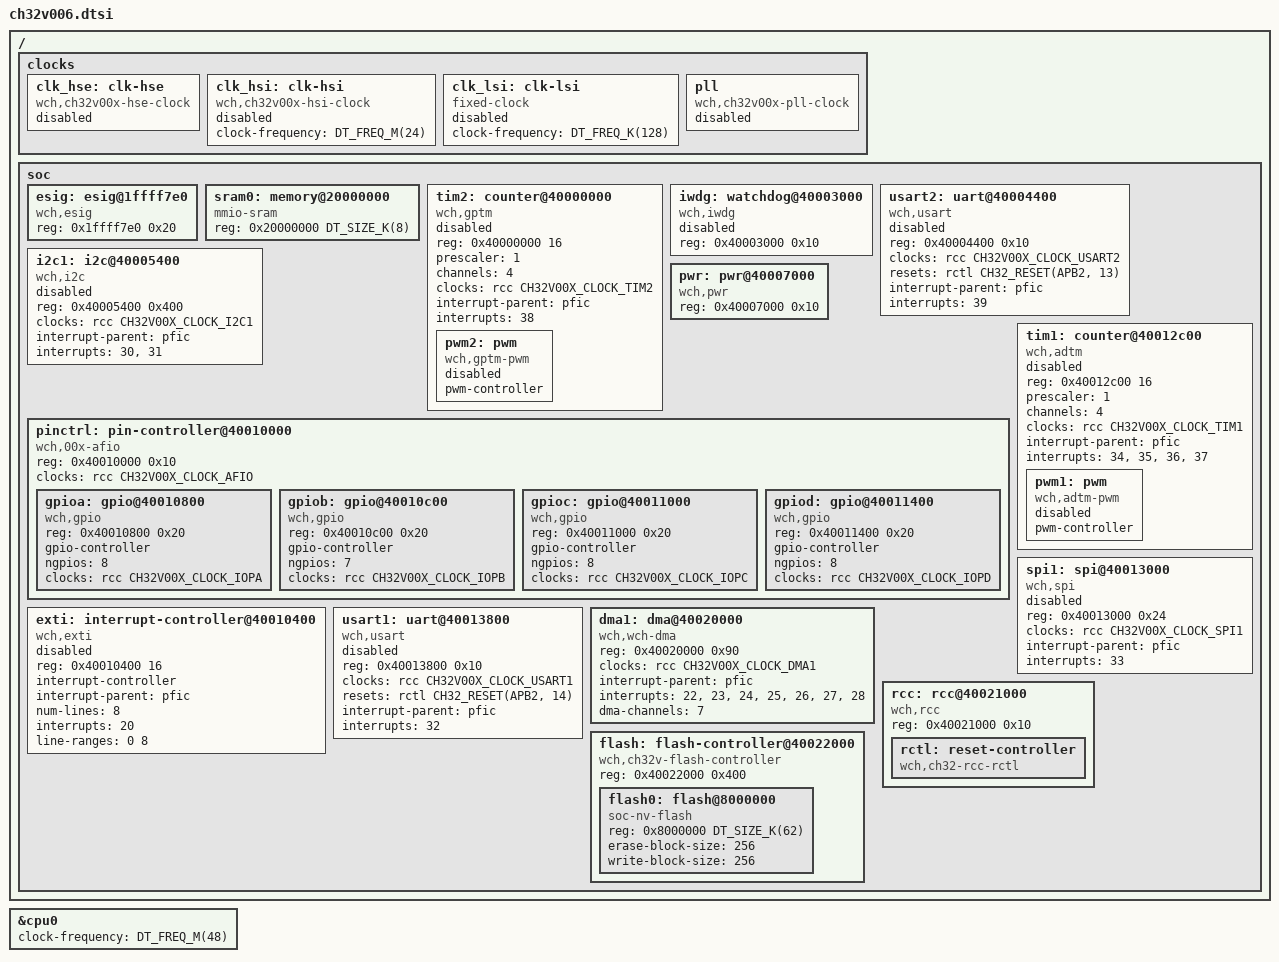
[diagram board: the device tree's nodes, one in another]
/*
 * Copyright (c) 2025 Michael Hope <michaelh@juju.nz>
 * Copyright (c) 2024 Paul Wedeck <paulwedeck@gmail.com>
 *
 * SPDX-License-Identifier: Apache-2.0
 */

#include <freq.h>
#include <mem.h>
#include <wch/qingke-v2c.dtsi>
#include <zephyr/dt-bindings/gpio/gpio.h>
#include <zephyr/dt-bindings/i2c/i2c.h>
#include <zephyr/dt-bindings/clock/ch32v00x-clocks.h>
#include <zephyr/dt-bindings/reset/ch32v00x-reset.h>
#include <zephyr/dt-bindings/dma/ch32v003-dma.h>

/ {
	clocks {
		clk_hse: clk-hse {
			compatible = "wch,ch32v00x-hse-clock";
			#clock-cells = <0>;
			status = "disabled";
		};

		clk_hsi: clk-hsi {
			compatible = "wch,ch32v00x-hsi-clock";
			#clock-cells = <0>;
			clock-frequency = <DT_FREQ_M(24)>;
			status = "disabled";
		};

		clk_lsi: clk-lsi {
			compatible = "fixed-clock";
			#clock-cells = <0>;
			clock-frequency = <DT_FREQ_K(128)>;
			status = "disabled";
		};

		pll: pll {
			compatible = "wch,ch32v00x-pll-clock";
			#clock-cells = <0>;
			status = "disabled";
		};
	};

	soc {
		esig: esig@1ffff7e0 {
			compatible = "wch,esig";
			reg = <0x1ffff7e0 0x20>;
		};

		sram0: memory@20000000 {
			compatible = "mmio-sram";
			reg = <0x20000000 DT_SIZE_K(8)>;
		};

		tim2: counter@40000000 {
			compatible = "wch,gptm";
			reg = <0x40000000 16>;
			prescaler = <1>;
			channels = <4>;
			clocks = <&rcc CH32V00X_CLOCK_TIM2>;
			interrupt-parent = <&pfic>;
			interrupts = <38>;
			interrupt-names = "global";
			status = "disabled";

			pwm2: pwm {
				compatible = "wch,gptm-pwm";
				pwm-controller;
				#pwm-cells = <3>;
				status = "disabled";
			};
		};

		iwdg: watchdog@40003000 {
			compatible = "wch,iwdg";
			reg = <0x40003000 0x10>;
			status = "disabled";
		};

		usart2: uart@40004400 {
			compatible = "wch,usart";
			reg = <0x40004400 0x10>;
			clocks = <&rcc CH32V00X_CLOCK_USART2>;
			resets = <&rctl CH32_RESET(APB2, 13)>;
			interrupt-parent = <&pfic>;
			interrupts = <39>;
			status = "disabled";
		};

		i2c1: i2c@40005400 {
			compatible = "wch,i2c";
			reg = <0x40005400 0x400>;
			#address-cells = <1>;
			#size-cells = <0>;
			clocks = <&rcc CH32V00X_CLOCK_I2C1>;
			interrupt-parent = <&pfic>;
			interrupts = <30>, <31>;
			status = "disabled";
		};

		pwr: pwr@40007000 {
			compatible = "wch,pwr";
			reg = <0x40007000 0x10>;
		};

		pinctrl: pin-controller@40010000 {
			compatible = "wch,00x-afio";
			reg = <0x40010000 0x10>;
			#address-cells = <1>;
			#size-cells = <1>;
			clocks = <&rcc CH32V00X_CLOCK_AFIO>;
			status = "okay";

			gpioa: gpio@40010800 {
				compatible = "wch,gpio";
				reg = <0x40010800 0x20>;
				gpio-controller;
				#gpio-cells = <2>;
				ngpios = <8>;
				clocks = <&rcc CH32V00X_CLOCK_IOPA>;
			};

			gpiob: gpio@40010c00 {
				compatible = "wch,gpio";
				reg = <0x40010c00 0x20>;
				gpio-controller;
				#gpio-cells = <2>;
				ngpios = <7>;
				clocks = <&rcc CH32V00X_CLOCK_IOPB>;
			};

			gpioc: gpio@40011000 {
				compatible = "wch,gpio";
				reg = <0x40011000 0x20>;
				gpio-controller;
				#gpio-cells = <2>;
				ngpios = <8>;
				clocks = <&rcc CH32V00X_CLOCK_IOPC>;
			};

			gpiod: gpio@40011400 {
				compatible = "wch,gpio";
				reg = <0x40011400 0x20>;
				gpio-controller;
				#gpio-cells = <2>;
				ngpios = <8>;
				clocks = <&rcc CH32V00X_CLOCK_IOPD>;
			};
		};

		exti: interrupt-controller@40010400 {
			compatible = "wch,exti";
			reg = <0x40010400 16>;
			interrupt-controller;
			#interrupt-cells = <1>;
			interrupt-parent = <&pfic>;
			num-lines = <8>;
			interrupts = <20>;
			line-ranges = <0 8>;
			interrupt-names = "line0-7";
			status = "disabled";
		};

		tim1: counter@40012c00 {
			compatible = "wch,adtm";
			reg = <0x40012c00 16>;
			prescaler = <1>;
			channels = <4>;
			clocks = <&rcc CH32V00X_CLOCK_TIM1>;
			interrupt-parent = <&pfic>;
			interrupts = <34>, <35>, <36>, <37>;
			interrupt-names = "brk", "up", "trg", "cc";
			status = "disabled";

			pwm1: pwm {
				compatible = "wch,adtm-pwm";
				pwm-controller;
				#pwm-cells = <3>;
				status = "disabled";
			};
		};

		spi1: spi@40013000 {
			compatible = "wch,spi";
			reg = <0x40013000 0x24>;
			clocks = <&rcc CH32V00X_CLOCK_SPI1>;
			interrupt-parent = <&pfic>;
			interrupts = <33>;
			#address-cells = <1>;
			#size-cells = <0>;
			status = "disabled";
		};

		usart1: uart@40013800 {
			compatible = "wch,usart";
			reg = <0x40013800 0x10>;
			clocks = <&rcc CH32V00X_CLOCK_USART1>;
			resets = <&rctl CH32_RESET(APB2, 14)>;
			interrupt-parent = <&pfic>;
			interrupts = <32>;
			status = "disabled";
		};

		dma1: dma@40020000 {
			compatible = "wch,wch-dma";
			reg = <0x40020000 0x90>;
			clocks = <&rcc CH32V00X_CLOCK_DMA1>;
			#dma-cells = <1>;
			interrupt-parent = <&pfic>;
			interrupts = <22>, <23>, <24>, <25>, <26>, <27>, <28>;
			dma-channels = <7>;
		};

		rcc: rcc@40021000 {
			compatible = "wch,rcc";
			reg = <0x40021000 0x10>;
			#clock-cells = <1>;
			status = "okay";

			rctl: reset-controller {
				compatible = "wch,ch32-rcc-rctl";
				#reset-cells = <1>;
			};
		};

		flash: flash-controller@40022000 {
			compatible = "wch,ch32v-flash-controller";
			reg = <0x40022000 0x400>;
			ranges;

			#address-cells = <1>;
			#size-cells = <1>;

			flash0: flash@8000000 {
				compatible = "soc-nv-flash";
				reg = <0x8000000 DT_SIZE_K(62)>;
				ranges = <0x0 0x08000000 DT_SIZE_K(62)>;
				erase-block-size = <256>;
				write-block-size = <256>;
				#address-cells = <1>;
				#size-cells = <1>;
			};
		};
	};
};

&cpu0 {
	clock-frequency = <DT_FREQ_M(48)>;
};
